# PIC32MK1024MCM100 register map
Vendor: Microchip
Registers are 32-bit, read-write, reset 0x0 unless marked. A register's access mark holds for its fields unless they carry their own. Addresses are absolute, and some are shared; only a register's first bit layout is shown; [hi:lo] are bit positions; {n}, {i} and the like mark numbered series.

## CAN3
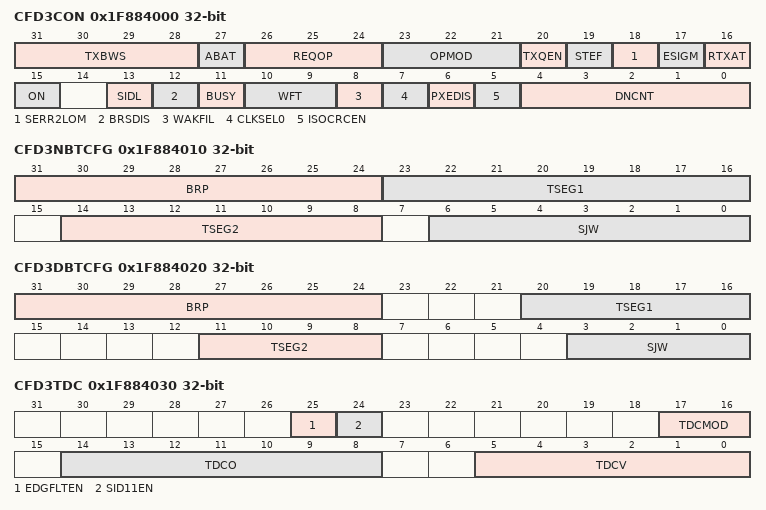
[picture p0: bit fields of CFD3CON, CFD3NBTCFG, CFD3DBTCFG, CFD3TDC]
0x1F884000 CFD3CON reset not defined — (power-on value xxxx01001000xxxx000x0xxxxxx00000)
  [31:28] TXBWS
  [27] ABAT — (can only be set)
  [26:24] REQOP
  [23:21] OPMOD ro
  [20] TXQEN
  [19] STEF
  [18] SERR2LOM
  [17] ESIGM
  [16] RTXAT
  [15] ON
  [13] SIDL
  [12] BRSDIS
  [11] BUSY ro
  [10:9] WFT
  [8] WAKFIL
  [7] CLKSEL0
  [6] PXEDIS
  [5] ISOCRCEN
  [4:0] DNCNT
0x1F884010 CFD3NBTCFG reset not defined — (power-on value xxxxxxxxxxxxxxxx-xxxxxxx-xxxxxxx)
  [31:24] BRP, [23:16] TSEG1, [14:8] TSEG2, [6:0] SJW
0x1F884020 CFD3DBTCFG reset not defined — (power-on value xxxxxxxx---xxxxx----xxxx----xxxx)
  [31:24] BRP, [20:16] TSEG1, [11:8] TSEG2, [3:0] SJW
0x1F884030 CFD3TDC reset not defined — (power-on value ------xx------xx-xxxxxxx--xxxxxx)
  [25] EDGFLTEN, [24] SID11EN, [17:16] TDCMOD, [14:8] TDCO, [5:0] TDCV
0x1F884040 CFD3TBC reset not defined — (power-on value xxxxxxxxxxxxxxxxxxxxxxxxxxxxxxxx)
  [31:0] TBC
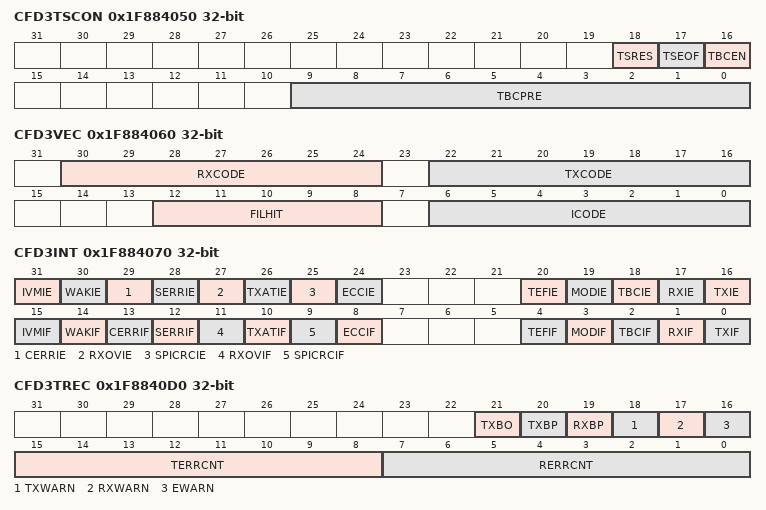
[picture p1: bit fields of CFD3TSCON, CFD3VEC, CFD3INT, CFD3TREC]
0x1F884050 CFD3TSCON reset not defined — (power-on value -------------xxx------xxxxxxxxxx)
  [18] TSRES, [17] TSEOF, [16] TBCEN, [9:0] TBCPRE
0x1F884060 CFD3VEC reset not defined — (power-on value 0xxxxxxx0xxxxxxx0000000001000000)
  [30:24] RXCODE, [22:16] TXCODE, [12:8] FILHIT ro, [6:0] ICODE ro
0x1F884070 CFD3INT reset not defined — (power-on value 00000xxx000x000000000xxx000x0000)
  [31] IVMIE, [30] WAKIE, [29] CERRIE, [28] SERRIE, [27] RXOVIE, [26] TXATIE, [25] SPICRCIE, [24] ECCIE, [20] TEFIE, [19] MODIE, [18] TBCIE, [17] RXIE, [16] TXIE, [15] IVMIF, [14] WAKIF, [13] CERRIF, [12] SERRIF, [11] RXOVIF, [10] TXATIF, [9] SPICRCIF, [8] ECCIF, [4] TEFIF, [3] MODIF, [2] TBCIF, [1] RXIF, [0] TXIF
0x1F884080 CFD3RXIF reset not defined — (power-on value xxxxxxxxxxxxxxxxxxxxxxxxxxxxxxx-)
  [31:1] RFIF
0x1F884090 CFD3TXIF reset not defined — (power-on value xxxxxxxxxxxxxxxxxxxxxxxxxxxxxxxx)
  [31:0] TFIF
0x1F8840A0 CFD3RXOVIF reset not defined — (power-on value xxxxxxxxxxxxxxxxxxxxxxxxxxxxxxx-)
  [31:1] RFOVIF
0x1F8840B0 CFD3TXATIF reset not defined — (power-on value xxxxxxxxxxxxxxxxxxxxxxxxxxxxxxxx)
  [31:0] TFATIF
0x1F8840C0 CFD3TXREQ reset not defined — (power-on value xxxxxxxxxxxxxxxxxxxxxxxxxxxxxxxx)
  [31:0] TXREQ
0x1F8840D0 CFD3TREC ro
  [21] TXBO, [20] TXBP, [19] RXBP, [18] TXWARN, [17] RXWARN, [16] EWARN, [15:8] TERRCNT, [7:0] RERRCNT
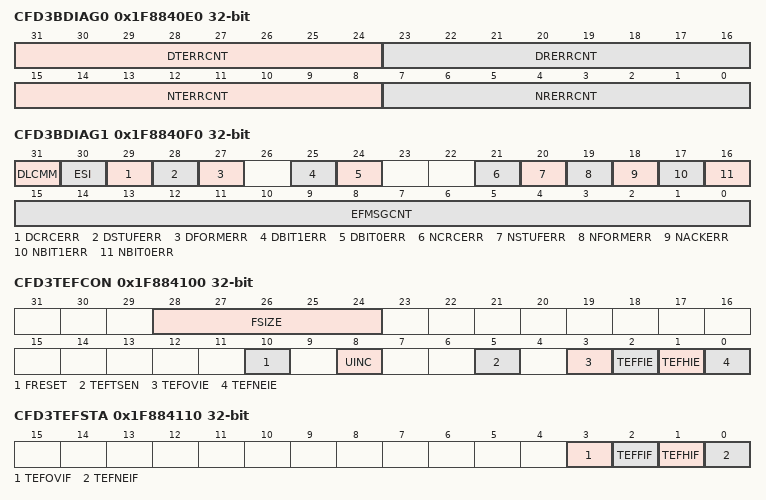
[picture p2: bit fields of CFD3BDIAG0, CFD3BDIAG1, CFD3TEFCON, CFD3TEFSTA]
0x1F8840E0 CFD3BDIAG0 reset not defined — (power-on value xxxxxxxxxxxxxxxxxxxxxxxxxxxxxxxx)
  [31:24] DTERRCNT, [23:16] DRERRCNT, [15:8] NTERRCNT, [7:0] NRERRCNT
0x1F8840F0 CFD3BDIAG1 reset not defined — (power-on value xxxxx-xx--xxxxxxxxxxxxxxxxxxxxxx)
  [31] DLCMM, [30] ESI, [29] DCRCERR, [28] DSTUFERR, [27] DFORMERR, [25] DBIT1ERR, [24] DBIT0ERR, [21] NCRCERR, [20] NSTUFERR, [19] NFORMERR, [18] NACKERR, [17] NBIT1ERR, [16] NBIT0ERR, [15:0] EFMSGCNT
0x1F884100 CFD3TEFCON reset not defined — (power-on value ---xxxxx-------------x-x--x-xxxx)
  [28:24] FSIZE, [10] FRESET, [8] UINC, [5] TEFTSEN, [3] TEFOVIE, [2] TEFFIE, [1] TEFHIE, [0] TEFNEIE
0x1F884110 CFD3TEFSTA reset not defined — (power-on value ----------------------------xxxx)
  [3] TEFOVIF, [2] TEFFIF, [1] TEFHIF, [0] TEFNEIF
0x1F884120 CFD3TEFUA reset not defined — (power-on value xxxxxxxxxxxxxxxxxxxxxxxxxxxxxxxx)
  [31:0] TEFUA
0x1F884130 CFD3FIFOBA reset not defined — (power-on value xxxxxxxxxxxxxxxxxxxxxxxxxxxxxxxx)
  [31:0] FIFOBA
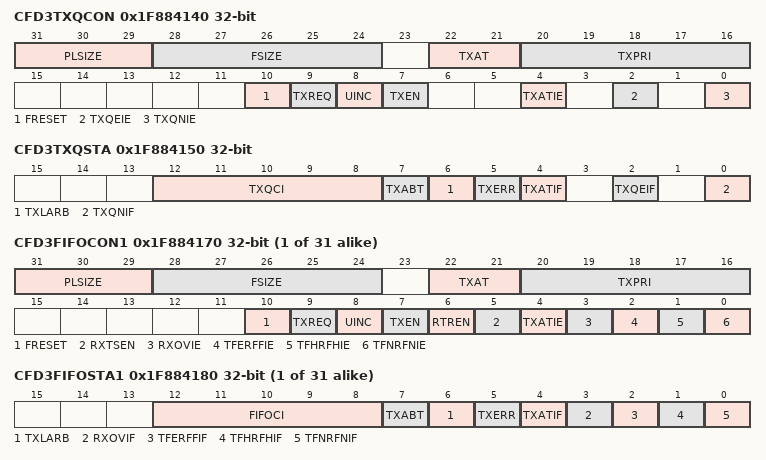
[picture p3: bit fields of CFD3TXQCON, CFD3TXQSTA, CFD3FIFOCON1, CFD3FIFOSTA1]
0x1F884140 CFD3TXQCON reset not defined — (power-on value xxxxxxxx-xxxxxxx-----xxxx--x-x-x)
  [31:29] PLSIZE, [28:24] FSIZE, [22:21] TXAT, [20:16] TXPRI, [10] FRESET, [9] TXREQ, [8] UINC, [7] TXEN, [4] TXATIE, [2] TXQEIE, [0] TXQNIE
0x1F884150 CFD3TXQSTA reset not defined — (power-on value -------------------xxxxxxxxx-x-x)
  [12:8] TXQCI, [7] TXABT, [6] TXLARB, [5] TXERR, [4] TXATIF, [2] TXQEIF, [0] TXQNIF
0x1F884160 CFD3TXQUA reset not defined — (power-on value xxxxxxxxxxxxxxxxxxxxxxxxxxxxxxxx)
  [31:0] TXQUA
{0x1F884140+0x30*i} CFD3FIFOCON{i} reset not defined (i=1..31) — (power-on value xxxxxxxx-xxxxxxx-----xxxxxxxxxxx)
  [31:29] PLSIZE, [28:24] FSIZE, [22:21] TXAT, [20:16] TXPRI, [10] FRESET, [9] TXREQ, [8] UINC, [7] TXEN, [6] RTREN, [5] RXTSEN, [4] TXATIE, [3] RXOVIE, [2] TFERFFIE, [1] TFHRFHIE, [0] TFNRFNIE
{0x1F884150+0x30*i} CFD3FIFOSTA{i} reset not defined (i=1..31) — (power-on value -------------------xxxxxxxxxxxxx)
  [12:8] FIFOCI, [7] TXABT, [6] TXLARB, [5] TXERR, [4] TXATIF, [3] RXOVIF, [2] TFERFFIF, [1] TFHRFHIF, [0] TFNRFNIF
{0x1F884160+0x30*i} CFD3FIFOUA{i} reset not defined (i=1..31) — (power-on value xxxxxxxxxxxxxxxxxxxxxxxxxxxxxxxx)
  [31:0] FIFOUA
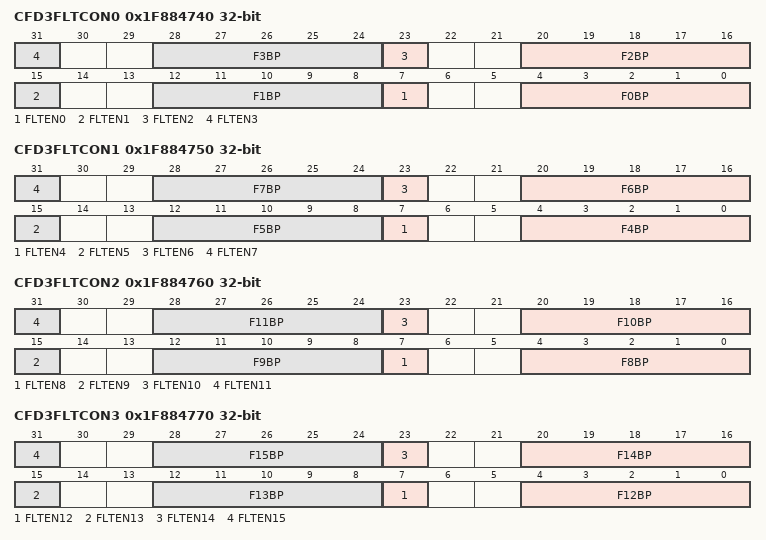
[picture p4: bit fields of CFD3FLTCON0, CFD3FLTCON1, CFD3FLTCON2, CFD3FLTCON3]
0x1F884740 CFD3FLTCON0 reset not defined — (power-on value x--xxxxxx--xxxxxx--xxxxxx--xxxxx)
  [8n+7] FLTEN{n} (n=0..3), [8n+4:8n] F{n}BP (n=0..3)
0x1F884750 CFD3FLTCON1 reset not defined — (power-on value x--xxxxxx--xxxxxx--xxxxxx--xxxxx)
  [8n-25] FLTEN{n} (n=4..7), [8n-28:8n-32] F{n}BP (n=4..7)
0x1F884760 CFD3FLTCON2 reset not defined — (power-on value x--xxxxxx--xxxxxx--xxxxxx--xxxxx)
  [8n-57] FLTEN{n} (n=8..11), [8n-60:8n-64] F{n}BP (n=8..11)
0x1F884770 CFD3FLTCON3 reset not defined — (power-on value x--xxxxxx--xxxxxx--xxxxxx--xxxxx)
  [8n-89] FLTEN{n} (n=12..15), [8n-92:8n-96] F{n}BP (n=12..15)
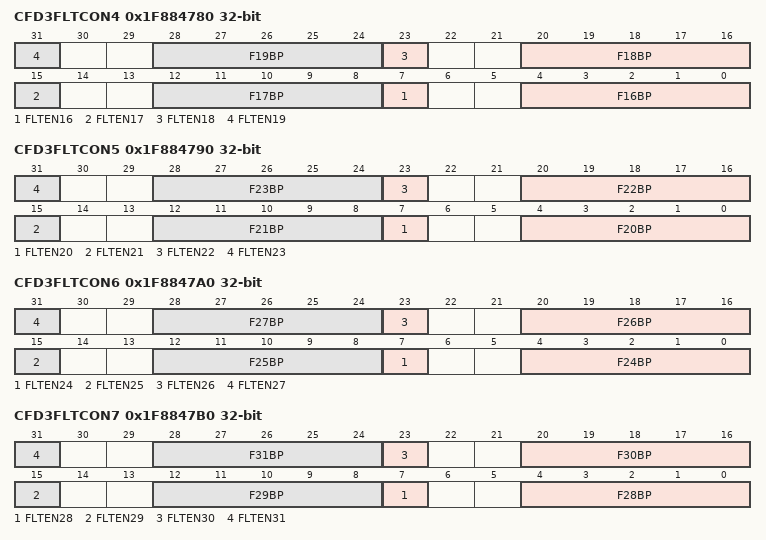
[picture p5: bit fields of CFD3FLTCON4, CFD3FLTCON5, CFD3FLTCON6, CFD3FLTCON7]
0x1F884780 CFD3FLTCON4 reset not defined — (power-on value x--xxxxxx--xxxxxx--xxxxxx--xxxxx)
  [8n-121] FLTEN{n} (n=16..19), [8n-124:8n-128] F{n}BP (n=16..19)
0x1F884790 CFD3FLTCON5 reset not defined — (power-on value x--xxxxxx--xxxxxx--xxxxxx--xxxxx)
  [8n-153] FLTEN{n} (n=20..23), [8n-156:8n-160] F{n}BP (n=20..23)
0x1F8847A0 CFD3FLTCON6 reset not defined — (power-on value x--xxxxxx--xxxxxx--xxxxxx--xxxxx)
  [8n-185] FLTEN{n} (n=24..27), [8n-188:8n-192] F{n}BP (n=24..27)
0x1F8847B0 CFD3FLTCON7 reset not defined — (power-on value x--xxxxxx--xxxxxx--xxxxxx--xxxxx)
  [8n-217] FLTEN{n} (n=28..31), [8n-220:8n-224] F{n}BP (n=28..31)
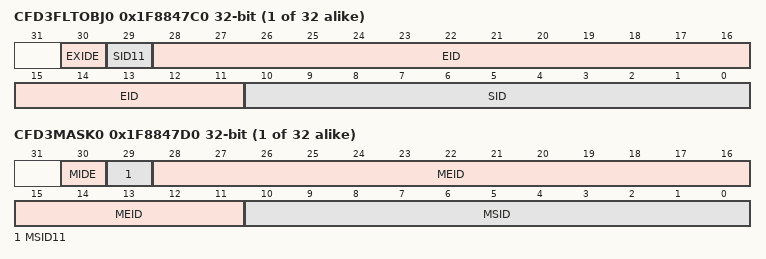
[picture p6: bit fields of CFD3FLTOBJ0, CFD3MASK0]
{0x1F8847C0+0x20*i} CFD3FLTOBJ{i} reset not defined (i=0..31) — (power-on value -xxxxxxxxxxxxxxxxxxxxxxxxxxxxxxx)
  [30] EXIDE, [29] SID11, [28:11] EID, [10:0] SID
{0x1F8847D0+0x20*i} CFD3MASK{i} reset not defined (i=0..31) — (power-on value -xxxxxxxxxxxxxxxxxxxxxxxxxxxxxxx)
  [30] MIDE, [29] MSID11, [28:11] MEID, [10:0] MSID
